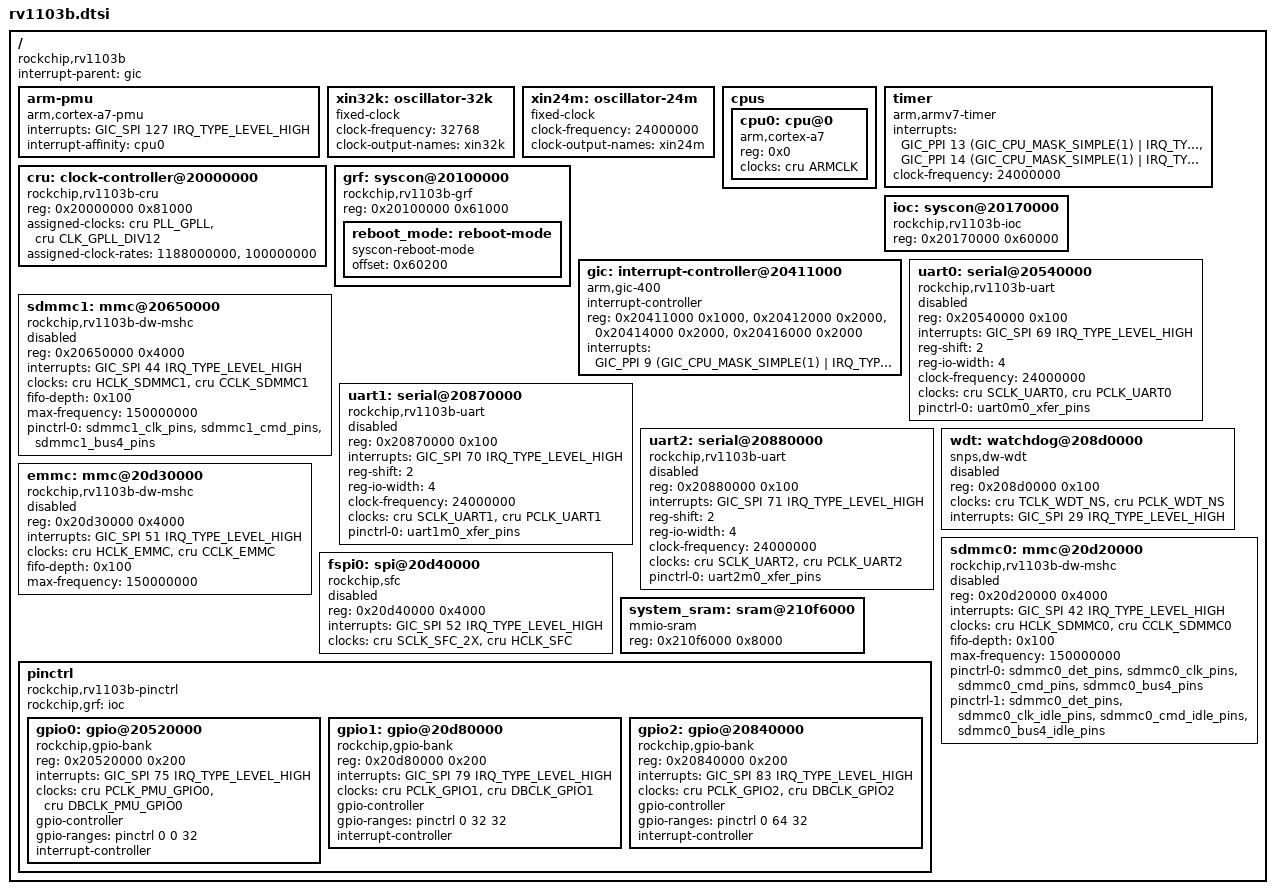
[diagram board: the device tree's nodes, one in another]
// SPDX-License-Identifier: (GPL-2.0+ OR MIT)
/*
 * Copyright (c) 2024 Rockchip Electronics Co., Ltd.
 */

#include <dt-bindings/clock/rockchip,rv1103b-cru.h>
#include <dt-bindings/gpio/gpio.h>
#include <dt-bindings/interrupt-controller/irq.h>
#include <dt-bindings/interrupt-controller/arm-gic.h>
#include <dt-bindings/pinctrl/rockchip.h>

/ {
	#address-cells = <1>;
	#size-cells = <1>;

	compatible = "rockchip,rv1103b";

	interrupt-parent = <&gic>;

	arm-pmu {
		compatible = "arm,cortex-a7-pmu";
		interrupts = <GIC_SPI 127 IRQ_TYPE_LEVEL_HIGH>;
		interrupt-affinity = <&cpu0>;
	};

	xin32k: oscillator-32k {
		compatible = "fixed-clock";
		clock-frequency = <32768>;
		clock-output-names = "xin32k";
		#clock-cells = <0>;
	};

	xin24m: oscillator-24m {
		compatible = "fixed-clock";
		clock-frequency = <24000000>;
		clock-output-names = "xin24m";
		#clock-cells = <0>;
	};

	cpus {
		#address-cells = <1>;
		#size-cells = <0>;

		cpu0: cpu@0 {
			device_type = "cpu";
			compatible = "arm,cortex-a7";
			reg = <0x0>;
			clocks = <&cru ARMCLK>;
		};
	};

	timer {
		compatible = "arm,armv7-timer";
		interrupts = <GIC_PPI 13 (GIC_CPU_MASK_SIMPLE(1) | IRQ_TYPE_LEVEL_HIGH)>,
			     <GIC_PPI 14 (GIC_CPU_MASK_SIMPLE(1) | IRQ_TYPE_LEVEL_HIGH)>;
		clock-frequency = <24000000>;
	};

	cru: clock-controller@20000000 {
		compatible = "rockchip,rv1103b-cru";
		reg = <0x20000000 0x81000>;
		#clock-cells = <1>;
		#reset-cells = <1>;

		assigned-clocks = <&cru PLL_GPLL>, <&cru CLK_GPLL_DIV12>;
		assigned-clock-rates = <1188000000>, <100000000>;
	};

	/*
	 * Merge all GRF, each independent GRF offset is shown as bellow:
	 * VEPU_GRF:		0x20100000
	 * NPU_GRF:		0x20110000
	 * VI_GRF:		0x20120000
	 * CPU_GRF:		0x20130000
	 * DDR_GRF:		0x20140000
	 * SYS_GRF:		0x20150000
	 * PMU_GRF:		0x20160000
	 */
	grf: syscon@20100000 {
		compatible = "rockchip,rv1103b-grf", "syscon", "simple-mfd";
		reg = <0x20100000 0x61000>;

		reboot_mode: reboot-mode {
			compatible = "syscon-reboot-mode";
			offset = <0x60200>;
		};
	};

	ioc: syscon@20170000 {
		compatible = "rockchip,rv1103b-ioc", "syscon";
		reg = <0x20170000 0x60000>;
	};

	gic: interrupt-controller@20411000 {
		compatible = "arm,gic-400";
		interrupt-controller;
		#interrupt-cells = <3>;
		#address-cells = <0>;

		reg = <0x20411000 0x1000>,
		      <0x20412000 0x2000>,
		      <0x20414000 0x2000>,
		      <0x20416000 0x2000>;
		interrupts = <GIC_PPI 9 (GIC_CPU_MASK_SIMPLE(1) | IRQ_TYPE_LEVEL_HIGH)>;
	};

	uart0: serial@20540000 {
		compatible = "rockchip,rv1103b-uart", "snps,dw-apb-uart";
		reg = <0x20540000 0x100>;
		interrupts = <GIC_SPI 69 IRQ_TYPE_LEVEL_HIGH>;
		reg-shift = <2>;
		reg-io-width = <4>;
		clock-frequency = <24000000>;
		clocks = <&cru SCLK_UART0>, <&cru PCLK_UART0>;
		clock-names = "baudclk", "apb_pclk";
		pinctrl-names = "default";
		pinctrl-0 = <&uart0m0_xfer_pins>;
		status = "disabled";
	};

	sdmmc1: mmc@20650000 {
		compatible = "rockchip,rv1103b-dw-mshc", "rockchip,rk3288-dw-mshc";
		reg = <0x20650000 0x4000>;
		interrupts = <GIC_SPI 44 IRQ_TYPE_LEVEL_HIGH>;
		clocks = <&cru HCLK_SDMMC1>, <&cru CCLK_SDMMC1>;
		clock-names = "biu", "ciu";
		fifo-depth = <0x100>;
		max-frequency = <150000000>;
		pinctrl-names = "default";
		pinctrl-0 = <&sdmmc1_clk_pins &sdmmc1_cmd_pins &sdmmc1_bus4_pins>;
		status = "disabled";
	};

	uart1: serial@20870000 {
		compatible = "rockchip,rv1103b-uart", "snps,dw-apb-uart";
		reg = <0x20870000 0x100>;
		interrupts = <GIC_SPI 70 IRQ_TYPE_LEVEL_HIGH>;
		reg-shift = <2>;
		reg-io-width = <4>;
		clock-frequency = <24000000>;
		clocks = <&cru SCLK_UART1>, <&cru PCLK_UART1>;
		clock-names = "baudclk", "apb_pclk";
		pinctrl-names = "default";
		pinctrl-0 = <&uart1m0_xfer_pins>;
		status = "disabled";
	};

	uart2: serial@20880000 {
		compatible = "rockchip,rv1103b-uart", "snps,dw-apb-uart";
		reg = <0x20880000 0x100>;
		interrupts = <GIC_SPI 71 IRQ_TYPE_LEVEL_HIGH>;
		reg-shift = <2>;
		reg-io-width = <4>;
		clock-frequency = <24000000>;
		clocks = <&cru SCLK_UART2>, <&cru PCLK_UART2>;
		clock-names = "baudclk", "apb_pclk";
		pinctrl-names = "default";
		pinctrl-0 = <&uart2m0_xfer_pins>;
		status = "disabled";
	};

	wdt: watchdog@208d0000 {
		compatible = "snps,dw-wdt";
		reg = <0x208d0000 0x100>;
		clocks = <&cru TCLK_WDT_NS>, <&cru PCLK_WDT_NS>;
		clock-names = "tclk", "pclk";
		interrupts = <GIC_SPI 29 IRQ_TYPE_LEVEL_HIGH>;
		status = "disabled";
	};

	sdmmc0: mmc@20d20000 {
		compatible = "rockchip,rv1103b-dw-mshc", "rockchip,rk3288-dw-mshc";
		reg = <0x20d20000 0x4000>;
		interrupts = <GIC_SPI 42 IRQ_TYPE_LEVEL_HIGH>;
		clocks = <&cru HCLK_SDMMC0>, <&cru CCLK_SDMMC0>;
		clock-names = "biu", "ciu";
		fifo-depth = <0x100>;
		max-frequency = <150000000>;
		pinctrl-names = "normal", "idle";
		pinctrl-0 = <&sdmmc0_det_pins
			     &sdmmc0_clk_pins
			     &sdmmc0_cmd_pins
			     &sdmmc0_bus4_pins>;
		pinctrl-1 = <&sdmmc0_det_pins
			     &sdmmc0_clk_idle_pins
			     &sdmmc0_cmd_idle_pins
			     &sdmmc0_bus4_idle_pins>;
		status = "disabled";
	};

	emmc: mmc@20d30000 {
		compatible = "rockchip,rv1103b-dw-mshc", "rockchip,rk3288-dw-mshc";
		reg = <0x20d30000 0x4000>;
		interrupts = <GIC_SPI 51 IRQ_TYPE_LEVEL_HIGH>;
		clocks = <&cru HCLK_EMMC>, <&cru CCLK_EMMC>;
		clock-names = "biu", "ciu";
		fifo-depth = <0x100>;
		max-frequency = <150000000>;
		status = "disabled";
	};

	fspi0: spi@20d40000 {
		compatible = "rockchip,sfc";
		reg = <0x20d40000 0x4000>;
		interrupts = <GIC_SPI 52 IRQ_TYPE_LEVEL_HIGH>;
		clocks = <&cru SCLK_SFC_2X>, <&cru HCLK_SFC>;
		clock-names = "clk_sfc", "hclk_sfc";
		#address-cells = <1>;
		#size-cells = <0>;
		status = "disabled";
	};

	system_sram: sram@210f6000 {
		compatible = "mmio-sram";
		reg = <0x210f6000 0x8000>;
		#address-cells = <1>;
		#size-cells = <1>;
		ranges = <0 0x210f6000 0x8000>;
	};

	pinctrl: pinctrl {
		compatible = "rockchip,rv1103b-pinctrl";
		rockchip,grf = <&ioc>;
		#address-cells = <1>;
		#size-cells = <1>;
		ranges;

		gpio0: gpio@20520000 {
			compatible = "rockchip,gpio-bank";
			reg = <0x20520000 0x200>;
			interrupts = <GIC_SPI 75 IRQ_TYPE_LEVEL_HIGH>;
			clocks = <&cru PCLK_PMU_GPIO0>, <&cru DBCLK_PMU_GPIO0>;
			gpio-controller;
			#gpio-cells = <2>;
			gpio-ranges = <&pinctrl 0 0 32>;
			interrupt-controller;
			#interrupt-cells = <2>;
		};

		gpio1: gpio@20d80000 {
			compatible = "rockchip,gpio-bank";
			reg = <0x20d80000 0x200>;
			interrupts = <GIC_SPI 79 IRQ_TYPE_LEVEL_HIGH>;
			clocks = <&cru PCLK_GPIO1>, <&cru DBCLK_GPIO1>;
			gpio-controller;
			#gpio-cells = <2>;
			gpio-ranges = <&pinctrl 0 32 32>;
			interrupt-controller;
			#interrupt-cells = <2>;
		};

		gpio2: gpio@20840000 {
			compatible = "rockchip,gpio-bank";
			reg = <0x20840000 0x200>;
			interrupts = <GIC_SPI 83 IRQ_TYPE_LEVEL_HIGH>;
			clocks = <&cru PCLK_GPIO2>, <&cru DBCLK_GPIO2>;
			gpio-controller;
			#gpio-cells = <2>;
			gpio-ranges = <&pinctrl 0 64 32>;
			interrupt-controller;
			#interrupt-cells = <2>;
		};
	};
};

#include "rv1103b-pinctrl.dtsi"
